# SAM9X75D1M device description
Architecture: ARM926EJ-S; Family: SAM9; Series: SAM9X7
Registers are 32-bit, read-write, reset 0x0 unless marked. A register's access mark holds for its fields unless they carry their own. Offsets are from the block's base; [hi:lo] are bit positions.

## SYSCWP — External Interrupt Controller
Instances: SYSCWP 0xFFFFFEDC
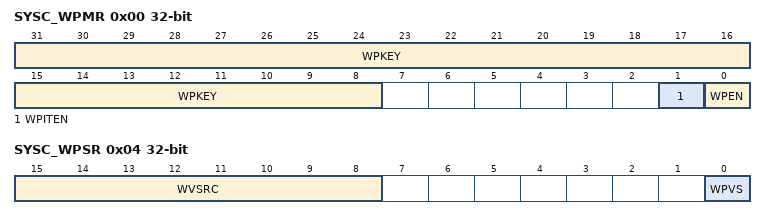
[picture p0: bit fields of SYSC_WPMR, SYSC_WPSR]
0x00 SYSC_WPMR — Write Protection Mode Register
  [31:8] WPKEY — Write Protection Key
    0x535943=PASSWD (Writing any other value in this field aborts the write operation of the WPEN and WPITEN bits. Always reads as 0.)
  [1] WPITEN — Write Protection RTC Interrupt Enable
    0=Disables the write protection of the RTC_IER/RTC_IDR configuration registers if WPKEY corresponds to 0x535943 ("SYC" in ASCII); 1=Enables the write protection of the RTC_IER/RTC_IDR configuration registers if WPKEY corresponds to 0x535943 ("SYC" in ASCII)
  [0] WPEN — Write Protection Enable
    0=Disables the write protection of the configuration registers if WPKEY corresponds to 0x535943 ("SYC" in ASCII); 1=Enables the write protection of the configuration registers if WPKEY corresponds to 0x535943 ("SYC" in ASCII)
0x04 SYSC_WPSR ro — Write Protection Status Register
  [15:8] WVSRC — Write Violation Source
  [0] WPVS — Write Protection Register Violation Status
    0=No write protection violation has occurred since the last read of SYSC_WPSR; 1=A write protection violation has occurred since the last read of SYSC_WPSR. The associated violation is reported into field WVSRC.

## WDT — Watchdog Timer
Instances: WDT 0xFFFFFF80
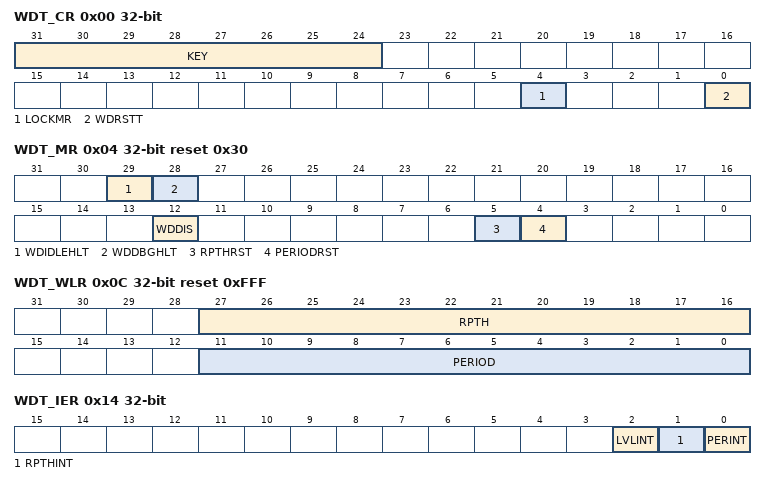
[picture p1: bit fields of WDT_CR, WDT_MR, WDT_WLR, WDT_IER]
0x00 WDT_CR wo reset not defined — Control Register
  [31:24] KEY — Password
    165=PASSWD (Writing any other value in this field aborts the write operation.)
  [4] LOCKMR — Lock Mode Register Write Access
    0=No effect; 1=Locks the configuration registers if KEY is written to 0xA5. Write accesses to WDT_MR, WDT_WLR and WDT_ILR have no effect.
  [0] WDRSTT — Watchdog Restart
    0=No effect; 1=Restarts the WDT if KEY is written to 0xA5
0x04 WDT_MR reset 0x30 — Mode Register
  [29] WDIDLEHLT — Watchdog Idle Halt
    0=The WDT runs when the system is in idle state; 1=The WDT stops when the system is in idle state
  [28] WDDBGHLT — Watchdog Debug Halt
    0=The WDT runs when the processor is in debug state; 1=The WDT stops when the processor is in debug state
  [12] WDDIS — Watchdog Disable
    0=Enables the WDT; 1=Disables the WDT
  [5] RPTHRST — Minimum Restart Period
    0=No reset is generated if the WDT is restarted before the RPTH threshold; 1=A reset is generated if the WDT is restarted before the RPTH threshold
  [4] PERIODRST — Period Reset
    0=No reset is generated if the WDT down counter reaches 0; 1=A reset is generated once the WDT down counter reaches 0
0x08 WDT_VR ro — Value Register
  [11:0] COUNTER — Watchdog Down Counter Value
0x0C WDT_WLR reset 0xFFF — Window Level Register
  [27:16] RPTH — Repeat Threshold
  [11:0] PERIOD — Watchdog Period
0x10 WDT_ILR reset 0xFFF — Interrupt Level Register
  [11:0] LVLTH — Level Threshold
0x14 WDT_IER wo reset not defined (atomic set of WDT_IMR) — Interrupt Enable Register
  [2] LVLINT — Interrupt Level Threshold Interrupt Enable
  [1] RPTHINT — Repeat Threshold Interrupt Enable
  [0] PERINT — Period Interrupt Enable
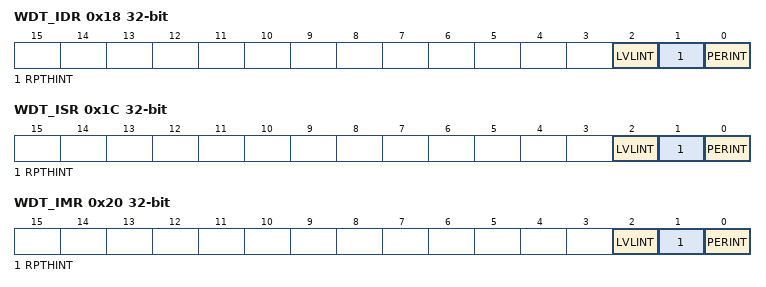
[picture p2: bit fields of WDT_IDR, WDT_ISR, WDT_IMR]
0x18 WDT_IDR wo reset not defined (atomic clear of WDT_IMR) — Interrupt Disable Register
  [2] LVLINT — Interrupt Level Threshold Interrupt Disable
  [1] RPTHINT — Repeat Threshold Interrupt Disable
  [0] PERINT — Period Interrupt Disable
0x1C WDT_ISR ro — Interrupt Status Register
  [2] LVLINT — Interrupt Level Threshold Interrupt Status (cleared on read)
    0=No level threshold failure has occurred in the WDT since the last read of WDT_ISR; 1=At least one level threshold failure has occurred in the WDT since the last read of WDT_ISR
  [1] RPTHINT — Repeat Threshold Interrupt Status (cleared on read)
    0=No repeat threshold failure has occurred in the WDT since the last read of WDT_ISR; 1=At least one repeat threshold failure has occurred in the WDT since the last read of WDT_ISR
  [0] PERINT — Period Interrupt Status (cleared on read)
    0=No period failure has occurred in the WDT since the last read of WDT_ISR; 1=At least one period failure has occurred in the WDT since the last read of WDT_ISR
0x20 WDT_IMR ro — Interrupt Mask Register
  [2] LVLINT — Interrupt Level Threshold Interrupt Mask
  [1] RPTHINT — Repeat Threshold Interrupt Mask
  [0] PERINT — Period Interrupt Mask
